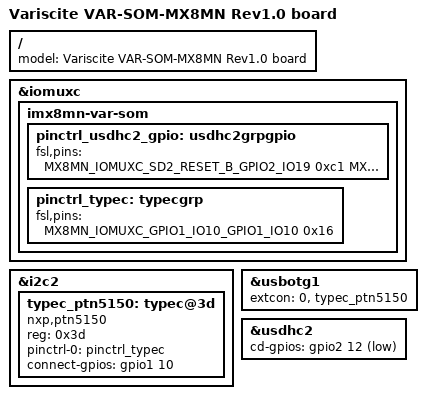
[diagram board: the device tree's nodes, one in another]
/*
 * Copyright 2018 NXP
 * Copyright 2019-2020 Variscite Ltd.
 *
 * This program is free software; you can redistribute it and/or
 * modify it under the terms of the GNU General Public License
 * as published by the Free Software Foundation; either version 2
 * of the License, or (at your option) any later version.
 *
 * This program is distributed in the hope that it will be useful,
 * but WITHOUT ANY WARRANTY; without even the implied warranty of
 * MERCHANTABILITY or FITNESS FOR A PARTICULAR PURPOSE.  See the
 * GNU General Public License for more details.
 */

/dts-v1/;

#include "fsl-imx8mn-var-som.dts"

/ {
	model = "Variscite VAR-SOM-MX8MN Rev1.0 board";
};

&iomuxc {
	imx8mn-var-som {
		pinctrl_usdhc2_gpio: usdhc2grpgpio {
			fsl,pins = <
				MX8MN_IOMUXC_SD2_RESET_B_GPIO2_IO19	0xc1
				MX8MN_IOMUXC_SD2_CD_B_GPIO2_IO12	0xc1
			>;
		};

		pinctrl_typec: typecgrp {
			fsl,pins = <
				MX8MN_IOMUXC_GPIO1_IO10_GPIO1_IO10	0x16
			>;
		};
	};
};

&i2c2 {
	/* USB-C controller */
	typec_ptn5150: typec@3d {
		status = "okay";
		compatible = "nxp,ptn5150";
		reg = <0x3d>;
		pinctrl-names = "default";
		pinctrl-0 = <&pinctrl_typec>;
		connect-gpios = <&gpio1 10 GPIO_ACTIVE_HIGH>;
	};
};

&usbotg1 {
	extcon = <0>, <&typec_ptn5150>;
};

&usdhc2 {
	cd-gpios = <&gpio2 12 GPIO_ACTIVE_LOW>;
};
